# STM32F401x register map
File version: 1.0
Registers are 32-bit, read-write, reset 0x0 unless marked. A register's access mark holds for its fields unless they carry their own. Offsets are from the block's base; [hi:lo] are bit positions; {n}, {i} and the like mark numbered series.

## USART6 — Universal synchronous asynchronous receiver transmitter
Base 0x40011400
Same registers: USART2 0x40004400, USART3 0x40004800, USART1 0x40011000
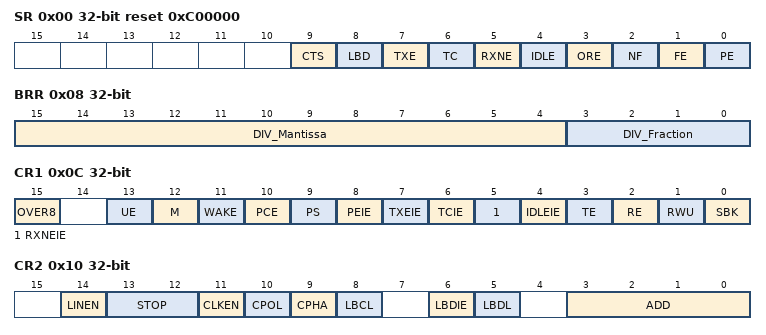
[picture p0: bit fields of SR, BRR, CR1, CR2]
0x00 SR access per field reset 0xC00000 — Status register
  [9] CTS rw — CTS flag
  [8] LBD rw — LIN break detection flag
  [7] TXE ro — Transmit data register empty
  [6] TC rw — Transmission complete
  [5] RXNE rw — Read data register not empty
  [4] IDLE ro — IDLE line detected
  [3] ORE ro — Overrun error
  [2] NF ro — Noise detected flag
  [1] FE ro — Framing error
  [0] PE ro — Parity error
0x04 DR — Data register
  [8:0] DR — Data value
0x08 BRR — Baud rate register
  [15:4] DIV_Mantissa — mantissa of USARTDIV
  [3:0] DIV_Fraction — fraction of USARTDIV
0x0C CR1 — Control register 1
  [15] OVER8 — Oversampling mode
  [13] UE — USART enable
  [12] M — Word length
  [11] WAKE — Wakeup method
  [10] PCE — Parity control enable
  [9] PS — Parity selection
  [8] PEIE — PE interrupt enable
  [7] TXEIE — TXE interrupt enable
  [6] TCIE — Transmission complete interrupt enable
  [5] RXNEIE — RXNE interrupt enable
  [4] IDLEIE — IDLE interrupt enable
  [3] TE — Transmitter enable
  [2] RE — Receiver enable
  [1] RWU — Receiver wakeup
  [0] SBK — Send break
0x10 CR2 — Control register 2
  [14] LINEN — LIN mode enable
  [13:12] STOP — STOP bits
  [11] CLKEN — Clock enable
  [10] CPOL — Clock polarity
  [9] CPHA — Clock phase
  [8] LBCL — Last bit clock pulse
  [6] LBDIE — LIN break detection interrupt enable
  [5] LBDL — lin break detection length
  [3:0] ADD — Address of the USART node
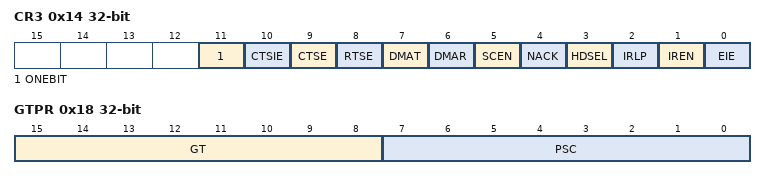
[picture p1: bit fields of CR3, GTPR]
0x14 CR3 — Control register 3
  [11] ONEBIT — One sample bit method enable
  [10] CTSIE — CTS interrupt enable
  [9] CTSE — CTS enable
  [8] RTSE — RTS enable
  [7] DMAT — DMA enable transmitter
  [6] DMAR — DMA enable receiver
  [5] SCEN — Smartcard mode enable
  [4] NACK — Smartcard NACK enable
  [3] HDSEL — Half-duplex selection
  [2] IRLP — IrDA low-power
  [1] IREN — IrDA mode enable
  [0] EIE — Error interrupt enable
0x18 GTPR — Guard time and prescaler register
  [15:8] GT — Guard time value
  [7:0] PSC — Prescaler value

## CAN1 — Controller area network
Base 0x40006400
Same registers: CAN2 0x40006800
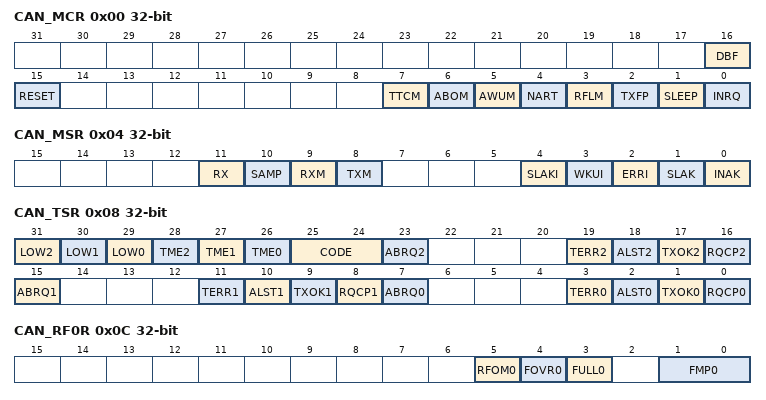
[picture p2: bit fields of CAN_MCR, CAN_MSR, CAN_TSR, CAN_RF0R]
0x00 CAN_MCR
  [16] DBF, [15] RESET, [7] TTCM, [6] ABOM, [5] AWUM, [4] NART, [3] RFLM, [2] TXFP, [1] SLEEP, [0] INRQ
0x04 CAN_MSR access per field
  [11] RX ro, [10] SAMP ro, [9] RXM ro, [8] TXM ro, [4] SLAKI rw, [3] WKUI rw, [2] ERRI rw, [1] SLAK ro, [0] INAK ro
0x08 CAN_TSR access per field
  [31] LOW2 ro — Lowest priority flag for mailbox 2
  [30] LOW1 ro — Lowest priority flag for mailbox 1
  [29] LOW0 ro — Lowest priority flag for mailbox 0
  [28] TME2 ro — Lowest priority flag for mailbox 2
  [27] TME1 ro — Lowest priority flag for mailbox 1
  [26] TME0 ro — Lowest priority flag for mailbox 0
  [25:24] CODE ro
  [23] ABRQ2 rw
  [19] TERR2 rw
  [18] ALST2 rw
  [17] TXOK2 rw
  [16] RQCP2 rw
  [15] ABRQ1 rw
  [11] TERR1 rw
  [10] ALST1 rw
  [9] TXOK1 rw
  [8] RQCP1 rw
  [7] ABRQ0 rw
  [3] TERR0 rw
  [2] ALST0 rw
  [1] TXOK0 rw
  [0] RQCP0 rw
0x0C CAN_RF0R access per field
  [5] RFOM0 rw, [4] FOVR0 rw, [3] FULL0 rw, [1:0] FMP0 ro
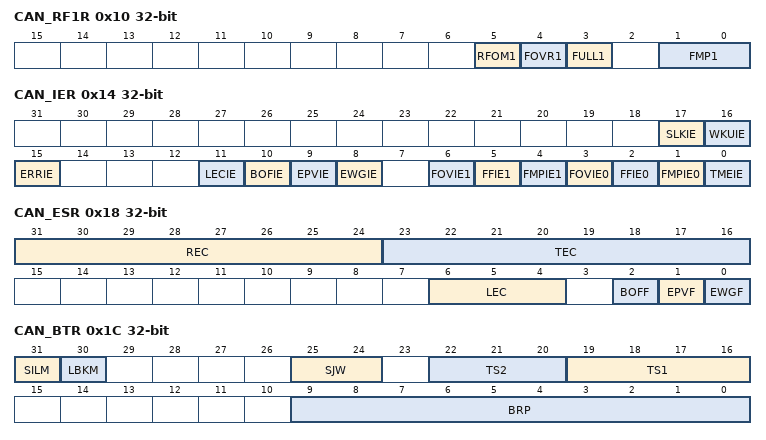
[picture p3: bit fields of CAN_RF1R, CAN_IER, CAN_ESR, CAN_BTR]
0x10 CAN_RF1R access per field
  [5] RFOM1 rw, [4] FOVR1 rw, [3] FULL1 rw, [1:0] FMP1 ro
0x14 CAN_IER
  [17] SLKIE, [16] WKUIE, [15] ERRIE, [11] LECIE, [10] BOFIE, [9] EPVIE, [8] EWGIE, [6] FOVIE1, [5] FFIE1, [4] FMPIE1, [3] FOVIE0, [2] FFIE0, [1] FMPIE0, [0] TMEIE
0x18 CAN_ESR access per field
  [31:24] REC ro, [23:16] TEC ro, [6:4] LEC rw, [2] BOFF ro, [1] EPVF ro, [0] EWGF ro
0x1C CAN_BTR
  [31] SILM, [30] LBKM, [25:24] SJW, [22:20] TS2, [19:16] TS1, [9:0] BRP
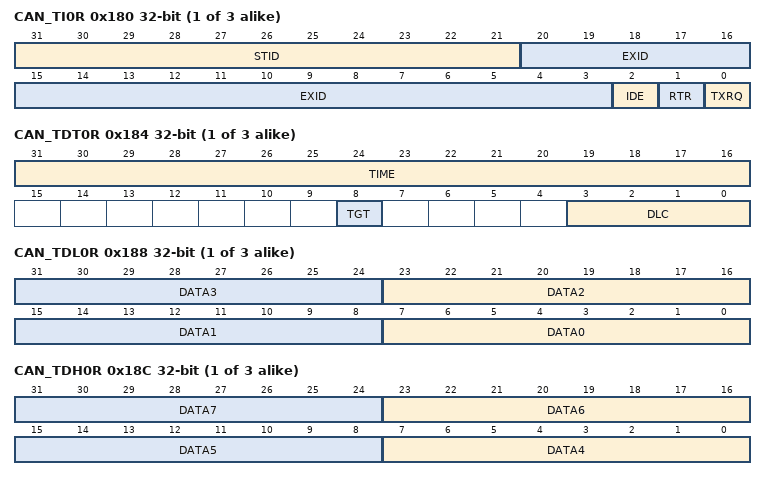
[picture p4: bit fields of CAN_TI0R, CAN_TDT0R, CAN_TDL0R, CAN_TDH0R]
{0x180+0x10*i} CAN_TI{i}R (i=0..2)
  [31:21] STID, [20:3] EXID, [2] IDE, [1] RTR, [0] TXRQ
{0x184+0x10*i} CAN_TDT{i}R (i=0..2)
  [31:16] TIME, [8] TGT, [3:0] DLC
{0x188+0x10*i} CAN_TDL{i}R (i=0..2)
  [8n+7:8n] DATA{n} (n=0..3)
{0x18C+0x10*i} CAN_TDH{i}R (i=0..2)
  [8n-25:8n-32] DATA{n} (n=4..7)
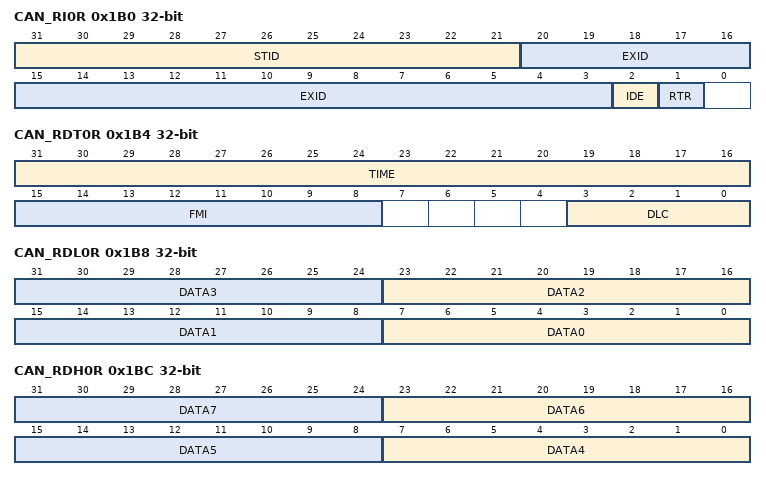
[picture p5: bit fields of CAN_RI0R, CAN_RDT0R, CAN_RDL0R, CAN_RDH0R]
0x1B0 CAN_RI0R ro
  [31:21] STID, [20:3] EXID, [2] IDE, [1] RTR
0x1B4 CAN_RDT0R ro
  [31:16] TIME, [15:8] FMI, [3:0] DLC
0x1B8 CAN_RDL0R ro
  [8n+7:8n] DATA{n} (n=0..3)
0x1BC CAN_RDH0R ro
  [8n-25:8n-32] DATA{n} (n=4..7)
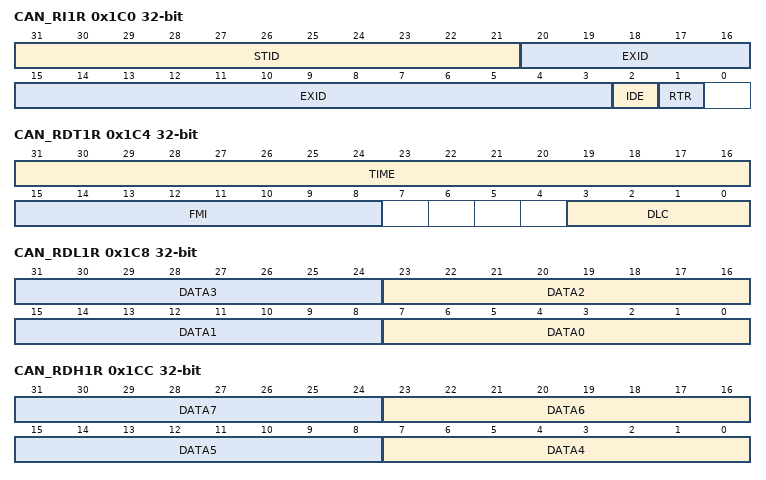
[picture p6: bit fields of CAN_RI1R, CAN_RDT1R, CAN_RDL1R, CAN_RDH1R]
0x1C0 CAN_RI1R ro
  [31:21] STID, [20:3] EXID, [2] IDE, [1] RTR
0x1C4 CAN_RDT1R ro
  [31:16] TIME, [15:8] FMI, [3:0] DLC
0x1C8 CAN_RDL1R ro
  [8n+7:8n] DATA{n} (n=0..3)
0x1CC CAN_RDH1R ro
  [8n-25:8n-32] DATA{n} (n=4..7)
0x200 CAN_FMR
  [0] FINIT
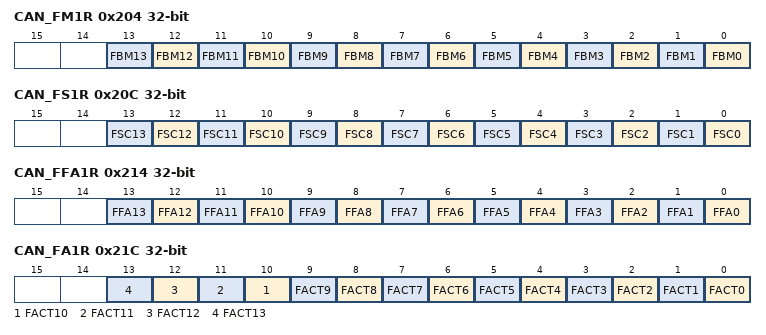
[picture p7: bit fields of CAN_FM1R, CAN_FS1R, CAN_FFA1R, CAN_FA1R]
0x204 CAN_FM1R
  [n] FBM{n} (n=0..13) — Filter mode
0x20C CAN_FS1R
  [n] FSC{n} (n=0..13) — Filter scale configuration
0x214 CAN_FFA1R
  [n] FFA{n} (n=0..13) — Filter FIFO assignment for filter {n}
0x21C CAN_FA1R
  [n] FACT{n} (n=0..13) — Filter active
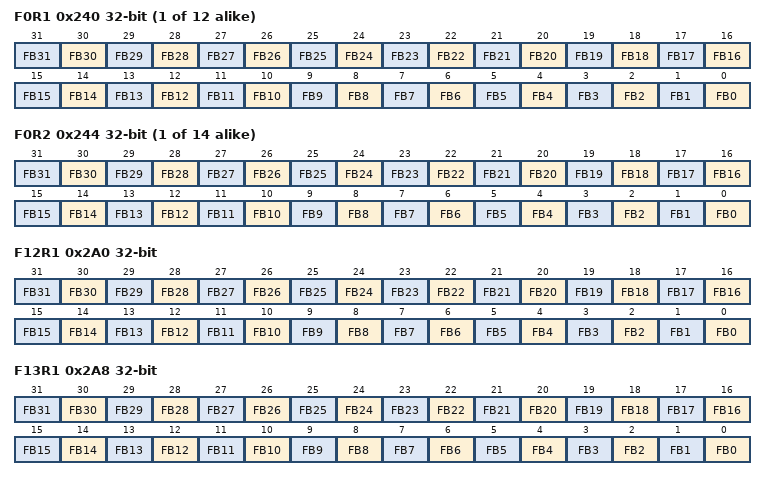
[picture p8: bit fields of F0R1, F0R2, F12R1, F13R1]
{0x240+8i} F{i}R1 (i=0..11) — Filter bank {i} register 1
  [n] FB{n} (n=0..31) — Filter bits
{0x244+8i} F{i}R2 (i=0..13) — Filter bank {i} register 2
  [n] FB{n} (n=0..31) — Filter bits
0x2A0 F12R1 — Filter bank 4 register 1
  [n] FB{n} (n=0..31) — Filter bits
0x2A8 F13R1 — Filter bank 13 register 1
  [n] FB{n} (n=0..31) — Filter bits
